# dm648_cslr_pll1_001 register map
Vendor: Texas Instruments
Peripheral module from a debugger description file.
Registers are 32-bit, access not given, reset 0x0 unless marked. A register's access mark holds for its fields unless they carry their own. Offsets are as the file gives them; lines under a group give offsets from that group; [hi:lo] are bit positions; {n}, {i} and the like mark numbered series; 'fields as' and 'values as' point back to an identical list; <NAME> marks a mode.

## PLL1 — PLL1 Module
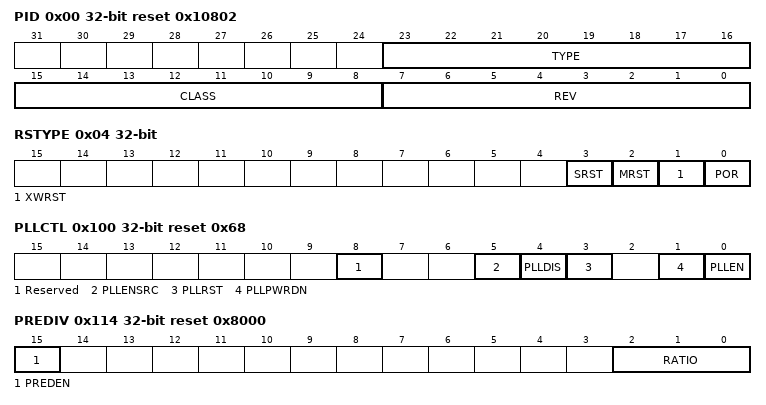
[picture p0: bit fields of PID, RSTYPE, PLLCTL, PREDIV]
0x00 PID reset 0x10802 — PLL Peripheral ID Register
  [23:16] TYPE ro — Peripheral type
  [15:8] CLASS ro — Peripheral class
  [7:0] REV ro — Peripheral revision
0x04 RSTYPE — PLL Reset Type Status Register
  [3] SRST ro — Sytesm reset, If 1, system reset was the reset to occur that is of highest priority
  [2] MRST ro — Maximum reset, If 1, mamimum reset was the reset to occur that is of highest priority
  [1] XWRST ro — Warm reset, If 1, warm reset was the reset to occur that is of highest priority
  [0] POR ro — Power on reset, If 1, power on reset was the reset to occur that is of highest priority
0x100 PLLCTL reset 0x68 — PLL Control Register
  [8] Reserved — (access N)
  [5] PLLENSRC rw — PLL Mux Control Source
    0=PLLENBIT (PLLEN Mux is controlled by PLLCTL.PLLEN); 1=PLLENPI (PLLEN Mux is controlled by input pllen_pi)
  [4] PLLDIS rw — PLL enable/disable
    0=ENABLE (PLL Enabled); 1=DISABLE (PLL Disabled)
  [3] PLLRST rw — PLL reset
    0=PLL_IN_RESET (PLL reset asserted); 1=PLL_NOT_IN_RESET (PLL reset not asserted)
  [1] PLLPWRDN rw — PLL Power down
    0=POWERED_DOWN (PLL is powered down, no PLL operation); 1=POWERED_UP (PLL is powered up)
  [0] PLLEN rw — PLL mode enable
    0=BYPASS_MODE (PLL is operating in bypass mode); 1=PLL_MODE (PLL is operating in PLL mode)
0x110 PLLM reset 0x10 — PLL Multiplier Register
  [5:0] PLLM rw — PLL multiplier
0x114 PREDIV reset 0x8000 — PLL Pre-Divider Control Register
  [15] PREDEN rw — Pre Divider Enable/Disable
    0=DISABLED (Divider 1 disabled); 1=ENABLED (Divider 1 enabled)
  [2:0] RATIO rw — Divider Ratio
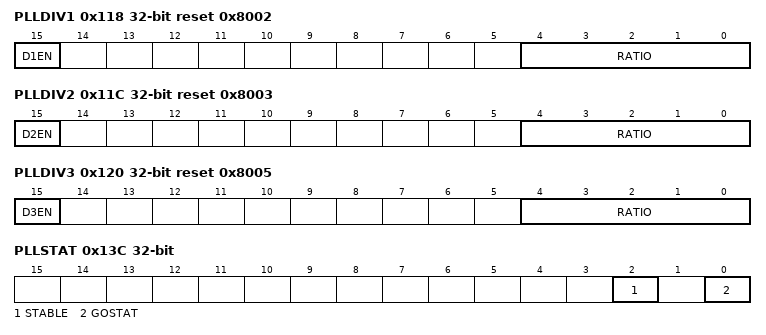
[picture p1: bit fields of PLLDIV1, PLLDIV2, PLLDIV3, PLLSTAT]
0x118 PLLDIV1 reset 0x8002 — PLL Controller Divider Register 1
  [15] D1EN rw — PLL divider 1 enable/disable
    values as PREDIV.PREDEN
  [4:0] RATIO rw — Divide by ratio
0x11C PLLDIV2 reset 0x8003 — PLL Controller Divider Register 2
  [15] D2EN rw — PLL divider 2 enable/disable
    0=DISABLED (Divider 2 disabled); 1=ENABLED (Divider 2 enabled)
  [4:0] RATIO rw — Divide by ratio
0x120 PLLDIV3 reset 0x8005 — PLL Controller Divider Register 3
  [15] D3EN rw — PLL divider 3 enable/disable
    0=DISABLED (Divider 3 disabled); 1=ENABLED (Divider 3 enabled)
  [4:0] RATIO rw — Divide by ratio
0x138 PLLCMD — PLL Controller Command Register
  [0] GOSET rw — GO bit for syscllk phase alignment
    0=CLEAR_BIT (Clears bit, has no effect); 1=SET_PHASE_ALIGNMENT (Sets clock phase alignment)
0x13C PLLSTAT — PLL Controller Status Register
  [2] STABLE ro — OSC counter done, oscillator assumedto be stable. This bit shold be 1 by time device comes out of reset.
    0=OSC_NOT_STABLE (OSC count not done, oscillator may not be stable); 1=OSC_STABLE (OSC count is done, oscilator assumed stable)
  [0] GOSTAT ro — Stauts of GO operation, If 1, go operation is still in progress.0 indicates GO not in progress
    0=GO_NOT_IN_PROGRESS (GO operation not in progress); 1=GO_IN_PROGRESS (GO operation in progess)
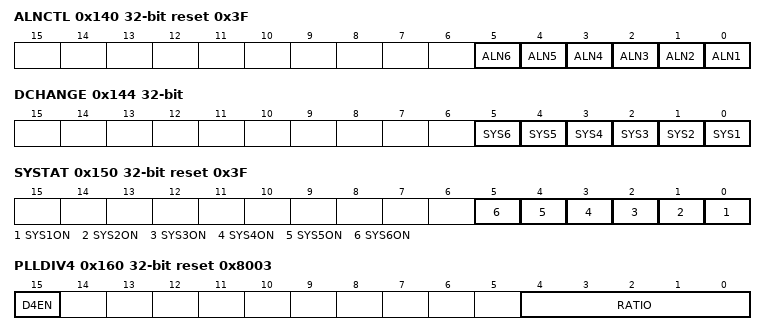
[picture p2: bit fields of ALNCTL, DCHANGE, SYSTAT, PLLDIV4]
0x140 ALNCTL reset 0x3F — PLL Controller Clock Align Register
  [all] fields
    0=NOT_ALIGNED (Clock not aligned with other system clocks); 1=ALIGNED (Clock aligned with other system clocks)
  [n-1] ALN{n} rw (n=1..6) — Align sysclk{n} with other system clocks chosen in align register
0x144 DCHANGE — PLLDIV Ratio Change Status Register
  [all] fields
    0=NOT_MODIFIED (Sysclk ratio has not been modified); 1=MODIFIED (Sysclk ratio has been modified)
  [n-1] SYS{n} rw (n=1..6) — Sysclk{n} divide ratio is modified
0x150 SYSTAT reset 0x3F — PLLDIV Ratio Change Status Register
  [all] fields
    0=OFF (Sysclk is off); 1=ON (Sysclk is on)
  [n-1] SYS{n}ON ro (n=1..6) — Sysclk{n} status
0x160 PLLDIV4 reset 0x8003 — PLL Controller Divider Register 4
  [15] D4EN rw — PLL divider 4 enable/disable
    values as PLLDIV3.D3EN
  [4:0] RATIO rw — Divide by ratio
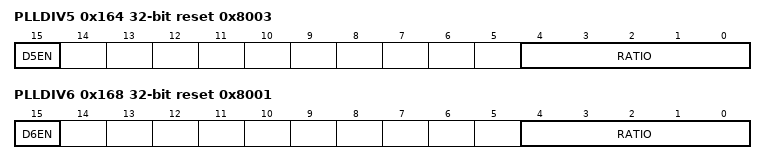
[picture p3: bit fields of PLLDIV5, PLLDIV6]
0x164 PLLDIV5 reset 0x8003 — PLL Controller Divider Register 5
  [15] D5EN rw — PLL divider 5 enable/disable
    values as PLLDIV3.D3EN
  [4:0] RATIO rw — Divide by ratio
0x168 PLLDIV6 reset 0x8001 — PLL Controller Divider Register 6
  [15] D6EN rw — PLL divider 6 enable/disable
    values as PLLDIV3.D3EN
  [4:0] RATIO rw — Divide by ratio
